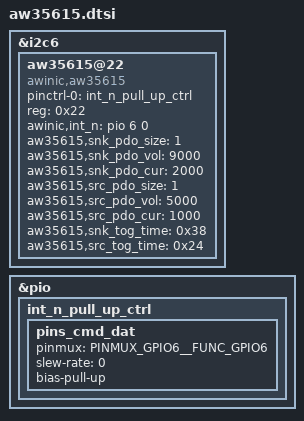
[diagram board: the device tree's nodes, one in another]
// SPDX-License-Identifier: GPL-2.0
&i2c6 {
	/*clock-frequency = <1000000>;*/
	status = "okay";
	aw35615@22 {
		pinctrl-names = "int_n_pullup";
		pinctrl-0 = <&int_n_pull_up_ctrl>;
		compatible = "awinic,aw35615";
		reg = <0x22>;
		awinic,int_n = <&pio 6 0>;
		aw35615,snk_pdo_size = <1>; /* set sink pdo num*/
		aw35615,snk_pdo_vol = <9000>; /* set sink pdo voltage mV*/
		aw35615,snk_pdo_cur = <2000>; /* set sink pdo current mA*/
		aw35615,src_pdo_size = <1>; /* set source pdo num*/
		aw35615,src_pdo_vol = <5000>; /* set source pdo voltage mV*/
		aw35615,src_pdo_cur = <1000>; /* set source pdo current mA*/
		aw35615,snk_tog_time = <0x38>; /* set toggle sink time */
		aw35615,src_tog_time = <0x24>; /* set toggle source time */
		status = "okay";
	};
};

&pio {
	int_n_pull_up_ctrl: int_n_pull_up_ctrl {
	pins_cmd_dat {
			pinmux = <PINMUX_GPIO6__FUNC_GPIO6>;
			slew-rate = <0>;
			bias-pull-up;
		};
	};
};
